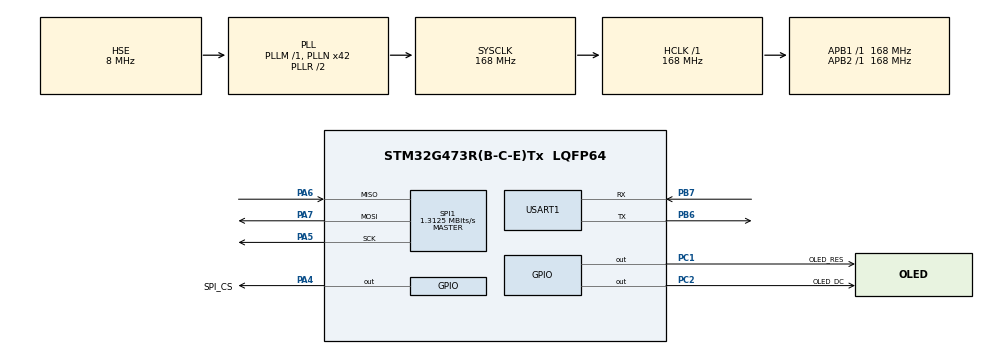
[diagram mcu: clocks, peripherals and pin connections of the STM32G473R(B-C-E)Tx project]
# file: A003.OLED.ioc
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Mcu.Family=STM32G4
Mcu.Name=STM32G473R(B-C-E)Tx
Mcu.Package=LQFP64
NVIC.PriorityGroup=NVIC_PRIORITYGROUP_4
PA13.Mode=Serial_Wire
PA13.Signal=SYS_JTMS-SWDIO
PA14.Mode=Serial_Wire
PA14.Signal=SYS_JTCK-SWCLK
PA4.GPIO_Label=SPI_CS
PA4.GPIO_PuPd=GPIO_NOPULL
PA4.GPIO_Speed=GPIO_SPEED_FREQ_HIGH
PA4.PinState=GPIO_PIN_RESET
PA4.Signal=GPIO_Output
PA5.Mode=Full_Duplex_Master
PA5.Signal=SPI1_SCK
PA6.Mode=Full_Duplex_Master
PA6.Signal=SPI1_MISO
PA7.Mode=Full_Duplex_Master
PA7.Signal=SPI1_MOSI
PB6.Mode=Asynchronous
PB6.Signal=USART1_TX
PB7.Mode=Asynchronous
PB7.Signal=USART1_RX
PC1.GPIO_Label=OLED_RES
PC1.GPIO_PuPd=GPIO_NOPULL
PC1.GPIO_Speed=GPIO_SPEED_FREQ_HIGH
PC1.PinState=GPIO_PIN_RESET
PC1.Signal=GPIO_Output
PC2.GPIO_Label=OLED_DC
PC2.GPIO_PuPd=GPIO_NOPULL
PC2.GPIO_Speed=GPIO_SPEED_FREQ_HIGH
PC2.PinState=GPIO_PIN_RESET
PC2.Signal=GPIO_Output
PF0-OSC_IN.Mode=HSE-External-Oscillator
PF0-OSC_IN.Signal=RCC_OSC_IN
PF1-OSC_OUT.Mode=HSE-External-Oscillator
PF1-OSC_OUT.Signal=RCC_OSC_OUT
ProjectManager.HeapSize=0x200
ProjectManager.StackSize=0x400
ProjectManager.TargetToolchain=MDK-ARM V5.27
RCC.ADC12Freq_Value=168000000
RCC.ADC345Freq_Value=168000000
RCC.AHBFreq_Value=168000000
RCC.APB1Freq_Value=168000000
RCC.APB1TimFreq_Value=168000000
RCC.APB2Freq_Value=168000000
RCC.APB2TimFreq_Value=168000000
RCC.CortexFreq_Value=168000000
RCC.EXTERNAL_CLOCK_VALUE=12288000
RCC.HCLKFreq_Value=168000000
RCC.HSE_VALUE=8000000
RCC.HSI48_VALUE=48000000
RCC.HSI_VALUE=16000000
RCC.LSE_VALUE=32768
RCC.PLLN=42
RCC.PLLSourceVirtual=RCC_PLLSOURCE_HSE
RCC.SYSCLKFreq_VALUE=168000000
RCC.SYSCLKSource=RCC_SYSCLKSOURCE_PLLCLK
RCC.USBFreq_Value=168000000
RCC.VCOOutputFreq_Value=336000000
SPI1.BaudRatePrescaler=SPI_BAUDRATEPRESCALER_128
SPI1.CLKPhase=SPI_PHASE_1EDGE
SPI1.CLKPolarity=SPI_POLARITY_LOW
SPI1.CalculateBaudRate=1.3125 MBits/s
SPI1.DataSize=SPI_DATASIZE_8BIT
SPI1.Direction=SPI_DIRECTION_2LINES
SPI1.Mode=SPI_MODE_MASTER
SPI1.VirtualType=VM_MASTER
USART1.VirtualMode-Asynchronous=VM_ASYNC
VP_SYS_VS_DBSignals.Mode=DisableDeadBatterySignals
board=custom

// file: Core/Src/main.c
/* USER CODE BEGIN Header */
/**
  ******************************************************************************
  * @file           : main.c
  * @brief          : Main program body
  ******************************************************************************
  * @attention
  *
  * <h2><center>&copy; Copyright (c) 2024 STMicroelectronics.
  * All rights reserved.</center></h2>
  *
  * This software component is licensed by ST under BSD 3-Clause license,
  * the "License"; You may not use this file except in compliance with the
  * License. You may obtain a copy of the License at:
  *                        opensource.org/licenses/BSD-3-Clause
  *
  ******************************************************************************
  */
/* USER CODE END Header */
#include "main.h"
#include "spi.h"
#include "usart.h"
#include "gpio.h"

/* USER CODE BEGIN Includes */
#include "oled.h"
/* USER CODE END Includes */

void SystemClock_Config(void);

int main(void)
{

  /* MCU Configuration--------------------------------------------------------*/

  /* Reset of all peripherals, Initializes the Flash interface and the Systick. */
  HAL_Init();

  /* Configure the system clock */
  SystemClock_Config();

  /* Initialize all configured peripherals */
  MX_GPIO_Init();
  MX_USART1_UART_Init();
  MX_SPI1_Init();
  /* USER CODE BEGIN 2 */
  OLED_Init();
  /* USER CODE END 2 */

  /* Infinite loop */
  /* USER CODE BEGIN WHILE */
  OLED_ShowString(10,10,"test", 12);
  // 更新显存到LCD
  OLED_Refresh_Gram();
  while (1)
  {
    /* USER CODE END WHILE */

    /* USER CODE BEGIN 3 */

    HAL_Delay(2000);
  }
  /* USER CODE END 3 */
}

void SystemClock_Config(void)
{
  RCC_OscInitTypeDef RCC_OscInitStruct = {0};
  RCC_ClkInitTypeDef RCC_ClkInitStruct = {0};
  RCC_PeriphCLKInitTypeDef PeriphClkInit = {0};

  /** Configure the main internal regulator output voltage
  */
  HAL_PWREx_ControlVoltageScaling(PWR_REGULATOR_VOLTAGE_SCALE1_BOOST);
  /** Initializes the RCC Oscillators according to the specified parameters
  * in the RCC_OscInitTypeDef structure.
  */
  RCC_OscInitStruct.OscillatorType = RCC_OSCILLATORTYPE_HSE;
  RCC_OscInitStruct.HSEState = RCC_HSE_ON;
  RCC_OscInitStruct.PLL.PLLState = RCC_PLL_ON;
  RCC_OscInitStruct.PLL.PLLSource = RCC_PLLSOURCE_HSE;
  RCC_OscInitStruct.PLL.PLLM = RCC_PLLM_DIV1;
  RCC_OscInitStruct.PLL.PLLN = 42;
  RCC_OscInitStruct.PLL.PLLP = RCC_PLLP_DIV2;
  RCC_OscInitStruct.PLL.PLLQ = RCC_PLLQ_DIV2;
  RCC_OscInitStruct.PLL.PLLR = RCC_PLLR_DIV2;
  if (HAL_RCC_OscConfig(&RCC_OscInitStruct) != HAL_OK)
  {
    Error_Handler();
  }
  /** Initializes the CPU, AHB and APB buses clocks
  */
  RCC_ClkInitStruct.ClockType = RCC_CLOCKTYPE_HCLK|RCC_CLOCKTYPE_SYSCLK
                              |RCC_CLOCKTYPE_PCLK1|RCC_CLOCKTYPE_PCLK2;
  RCC_ClkInitStruct.SYSCLKSource = RCC_SYSCLKSOURCE_PLLCLK;
  RCC_ClkInitStruct.AHBCLKDivider = RCC_SYSCLK_DIV1;
  RCC_ClkInitStruct.APB1CLKDivider = RCC_HCLK_DIV1;
  RCC_ClkInitStruct.APB2CLKDivider = RCC_HCLK_DIV1;

  if (HAL_RCC_ClockConfig(&RCC_ClkInitStruct, FLASH_LATENCY_4) != HAL_OK)
  {
    Error_Handler();
  }
  /** Initializes the peripherals clocks
  */
  PeriphClkInit.PeriphClockSelection = RCC_PERIPHCLK_USART1;
  PeriphClkInit.Usart1ClockSelection = RCC_USART1CLKSOURCE_PCLK2;
  if (HAL_RCCEx_PeriphCLKConfig(&PeriphClkInit) != HAL_OK)
  {
    Error_Handler();
  }
}

void Error_Handler(void)
{
  __disable_irq();
  while (1)
  {
  }
}

/************************ (C) COPYRIGHT STMicroelectronics *****END OF FILE****/
